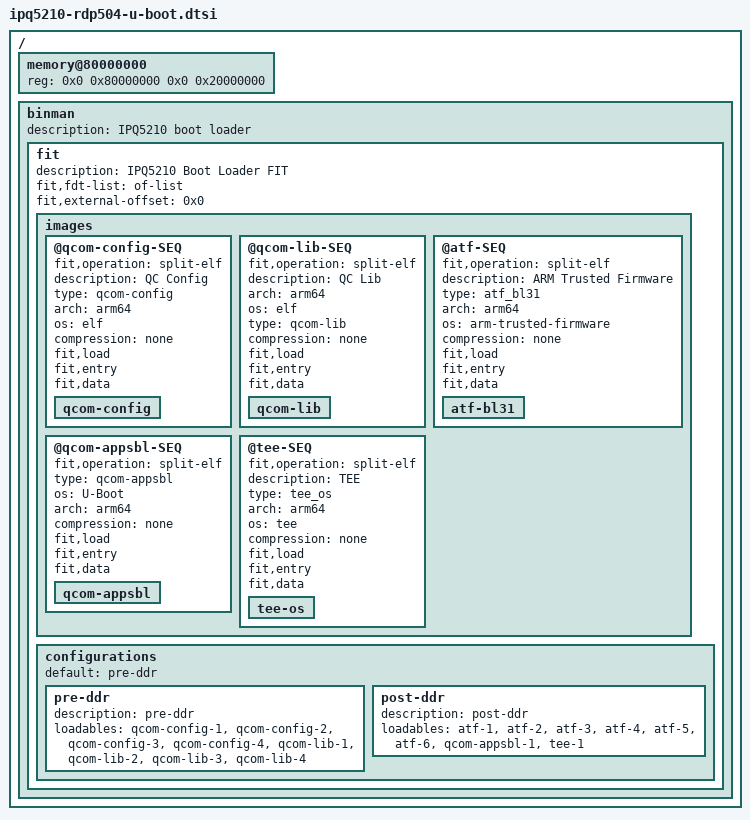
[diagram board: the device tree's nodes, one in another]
// SPDX-License-Identifier: GPL-2.0
/*
 * IPQ5210 RDP504 board device tree source
 *
 * Copyright (c) 2026 The Linux Foundation. All rights reserved.
 */

/ {
	/* Will be removed when SMEM parsing is updated */
	memory@80000000 {
		bootph-all;
		device_type = "memory";
		reg = <0x0 0x80000000 0x0 0x20000000>;
	};

	binman: binman {
		description = "IPQ5210 boot loader";
		fit {
			description = "IPQ5210 Boot Loader FIT";
			fit,fdt-list = "of-list";
			fit,external-offset = <0x0>;

			images {
				@qcom-config-SEQ {
					fit,operation = "split-elf";
					description = "QC Config";
					type = "qcom-config";
					arch = "arm64";
					os = "elf";
					compression = "none";
					fit,load;
					fit,entry;
					fit,data;

					qcom-config {
					};
				};

				@qcom-lib-SEQ {
					fit,operation = "split-elf";
					description = "QC Lib";
					arch = "arm64";
					os = "elf";
					type = "qcom-lib";
					compression = "none";
					fit,load;
					fit,entry;
					fit,data;

					qcom-lib {
					};
				};

				@atf-SEQ {
					fit,operation = "split-elf";
					description = "ARM Trusted Firmware";
					type = "atf_bl31";
					arch = "arm64";
					os = "arm-trusted-firmware";
					compression = "none";
					fit,load;
					fit,entry;
					fit,data;

					atf-bl31 {
					};
				};

				@qcom-appsbl-SEQ {
					fit,operation = "split-elf";
					type = "qcom-appsbl";
					os = "U-Boot";
					arch = "arm64";
					compression = "none";
					fit,load;
					fit,entry;
					fit,data;

					qcom-appsbl {
					};
				};

				@tee-SEQ {
					fit,operation = "split-elf";
					description = "TEE";
					type = "tee_os";
					arch = "arm64";
					os = "tee";
					compression = "none";
					fit,load;
					fit,entry;
					fit,data;

					tee-os {
					};
				};
			};

			configurations {
				default = "pre-ddr";

				pre-ddr {
					description = "pre-ddr";
					loadables = "qcom-config-1",
						    "qcom-config-2",
						    "qcom-config-3",
						    "qcom-config-4",
						    "qcom-lib-1",
						    "qcom-lib-2",
						    "qcom-lib-3",
						    "qcom-lib-4";
				};

				post-ddr {
					description = "post-ddr";
					loadables = "atf-1",
						    "atf-2",
						    "atf-3",
						    "atf-4",
						    "atf-5",
						    "atf-6",
						    "qcom-appsbl-1",
						    "tee-1";
				};
			};
		};
	};
};
